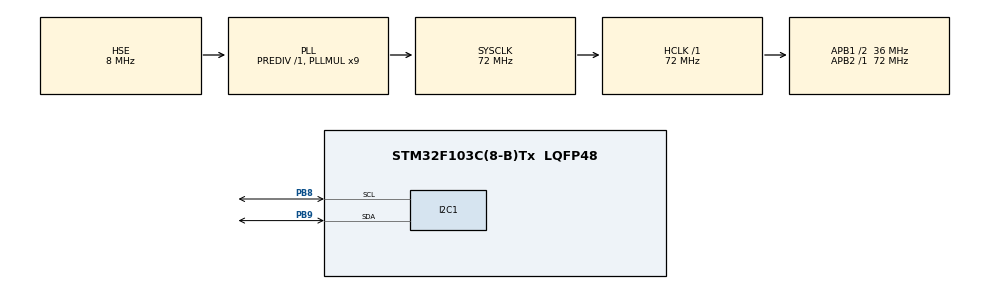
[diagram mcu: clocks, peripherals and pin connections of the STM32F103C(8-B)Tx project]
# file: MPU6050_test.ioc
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Mcu.Family=STM32F1
RCC.PLLSourceVirtual=RCC_PLLSOURCE_HSE
PD1-OSC_OUT.Mode=HSE-External-Oscillator
PD0-OSC_IN.Signal=RCC_OSC_IN
RCC.APB1CLKDivider=RCC_HCLK_DIV2
RCC.SYSCLKSource=RCC_SYSCLKSOURCE_PLLCLK
ProjectManager.StackSize=0x400
PD1-OSC_OUT.Signal=RCC_OSC_OUT
PA13.Signal=SYS_JTMS-SWDIO
ProjectManager.TargetToolchain=STM32CubeIDE
RCC.HCLKFreq_Value=72000000
PB9.Mode=I2C
RCC.APB2TimFreq_Value=72000000
RCC.USBFreq_Value=72000000
RCC.AHBFreq_Value=72000000
PD0-OSC_IN.Mode=HSE-External-Oscillator
board=custom
RCC.PLLMUL=RCC_PLL_MUL9
RCC.APB2Freq_Value=72000000
PA14.Mode=Serial_Wire
PA13.Mode=Serial_Wire
Mcu.Name=STM32F103C(8-B)Tx
RCC.SYSCLKFreq_VALUE=72000000
PB9.Signal=I2C1_SDA
Mcu.Package=LQFP48
PA14.Signal=SYS_JTCK-SWCLK
ProjectManager.HeapSize=0x200
NVIC.PriorityGroup=NVIC_PRIORITYGROUP_4
PB8.Mode=I2C
RCC.APB1TimFreq_Value=72000000
PB8.Signal=I2C1_SCL
RCC.APB1Freq_Value=36000000

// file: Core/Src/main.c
/* USER CODE BEGIN Header */
/**
  ******************************************************************************
  * @file           : main.c
  * @brief          : Main program body
  ******************************************************************************
  * @attention
  *
  * <h2><center>&copy; Copyright (c) 2021 STMicroelectronics.
  * All rights reserved.</center></h2>
  *
  * This software component is licensed by ST under BSD 3-Clause license,
  * the "License"; You may not use this file except in compliance with the
  * License. You may obtain a copy of the License at:
  *                        opensource.org/licenses/BSD-3-Clause
  *
  ******************************************************************************
  */
/* USER CODE END Header */
#include "main.h"

I2C_HandleTypeDef hi2c1;

/* USER CODE BEGIN PV */

static const uint8_t MPU_TempRegLSB = 0x41 << 1;
static const uint8_t MPU_TempRegMSB = 0x42 << 1;

/* USER CODE END PV */

void SystemClock_Config(void);
static void MX_GPIO_Init(void);
static void MX_I2C1_Init(void);

/* USER CODE BEGIN 0 */

#define MPU6050_ADDR 0x68 << 1
#define WHO_AM_I_REG 0X75
#define PWR_MGMT_1_REG 0x6B
#define SMPLRT_DIV 0x19
#define MPU_TempRegMSB 0x41

/* USER CODE END 0 */

int main(void)
{
  /* USER CODE BEGIN 1 */

	// En enumeration der beskriver en evt. fejl
	HAL_StatusTypeDef returnValue;
	uint8_t tempBuf[16];
	int16_t rawTempVal;
	float tempVal;

	void MPU6050_Init(void){
			uint8_t check, Data;

			// Check device ID who am I?
			// (Target device address, Internal memory address, Size of internal memory address, Pointer to data buffer, Amount of data to be sent, Timeout duration)
			HAL_I2C_Mem_Read(&hi2c1, MPU6050_ADDR, WHO_AM_I_REG, 1, &check, 1, 1000);

			if (check == 104){
				Data = 0;
				// Power management register 0x6B is set to all zeros to wake the device up
				HAL_I2C_Mem_Write(&hi2c1, MPU6050_ADDR, PWR_MGMT_1_REG, 1, &Data, 1 , 1000);

				// Set the data rate to 1 kHz by writing to SMPLRT_DIV register
				Data = 0x07;
				HAL_I2C_Mem_Write(&hi2c1, MPU6050_ADDR, SMPLRT_DIV, 1, &Data, 1 , 1000);
			}
		}

  /* USER CODE END 1 */

  /* MCU Configuration--------------------------------------------------------*/

  /* Reset of all peripherals, Initializes the Flash interface and the Systick. */
  HAL_Init();

  /* Configure the system clock */
  SystemClock_Config();

  /* Initialize all configured peripherals */
  MX_GPIO_Init();
  MX_I2C1_Init();
  /* USER CODE BEGIN 2 */

  MPU6050_Init();

  /* USER CODE END 2 */

  /* Infinite loop */
  /* USER CODE BEGIN WHILE */
  while (1)
  {
	  tempBuf[0] = MPU_TempRegMSB;

	  HAL_I2C_Mem_Read(&hi2c1, MPU6050_ADDR, MPU_TempRegMSB, 1, tempBuf, 2, HAL_MAX_DELAY);

		  // sammensætning af rå data
		  rawTempVal = ((int16_t)tempBuf[0] << 8 | tempBuf[1]);
		  tempVal = (rawTempVal)/340 + 36.53;
		  rawTempVal = ((int16_t)tempBuf[0] << 8 | tempBuf[1]);

    /* USER CODE END WHILE */

  }
}

void SystemClock_Config(void)
{
  RCC_OscInitTypeDef RCC_OscInitStruct = {0};
  RCC_ClkInitTypeDef RCC_ClkInitStruct = {0};

  /** Initializes the RCC Oscillators according to the specified parameters
  * in the RCC_OscInitTypeDef structure.
  */
  RCC_OscInitStruct.OscillatorType = RCC_OSCILLATORTYPE_HSE;
  RCC_OscInitStruct.HSEState = RCC_HSE_ON;
  RCC_OscInitStruct.HSEPredivValue = RCC_HSE_PREDIV_DIV1;
  RCC_OscInitStruct.HSIState = RCC_HSI_ON;
  RCC_OscInitStruct.PLL.PLLState = RCC_PLL_ON;
  RCC_OscInitStruct.PLL.PLLSource = RCC_PLLSOURCE_HSE;
  RCC_OscInitStruct.PLL.PLLMUL = RCC_PLL_MUL9;
  if (HAL_RCC_OscConfig(&RCC_OscInitStruct) != HAL_OK)
  {
    Error_Handler();
  }
  /** Initializes the CPU, AHB and APB buses clocks
  */
  RCC_ClkInitStruct.ClockType = RCC_CLOCKTYPE_HCLK|RCC_CLOCKTYPE_SYSCLK
                              |RCC_CLOCKTYPE_PCLK1|RCC_CLOCKTYPE_PCLK2;
  RCC_ClkInitStruct.SYSCLKSource = RCC_SYSCLKSOURCE_PLLCLK;
  RCC_ClkInitStruct.AHBCLKDivider = RCC_SYSCLK_DIV1;
  RCC_ClkInitStruct.APB1CLKDivider = RCC_HCLK_DIV2;
  RCC_ClkInitStruct.APB2CLKDivider = RCC_HCLK_DIV1;

  if (HAL_RCC_ClockConfig(&RCC_ClkInitStruct, FLASH_LATENCY_2) != HAL_OK)
  {
    Error_Handler();
  }
}

static void MX_I2C1_Init(void)
{

  hi2c1.Instance = I2C1;
  hi2c1.Init.ClockSpeed = 100000;
  hi2c1.Init.DutyCycle = I2C_DUTYCYCLE_2;
  hi2c1.Init.OwnAddress1 = 0;
  hi2c1.Init.AddressingMode = I2C_ADDRESSINGMODE_7BIT;
  hi2c1.Init.DualAddressMode = I2C_DUALADDRESS_DISABLE;
  hi2c1.Init.OwnAddress2 = 0;
  hi2c1.Init.GeneralCallMode = I2C_GENERALCALL_DISABLE;
  hi2c1.Init.NoStretchMode = I2C_NOSTRETCH_DISABLE;
  if (HAL_I2C_Init(&hi2c1) != HAL_OK)
  {
    Error_Handler();
  }

}

static void MX_GPIO_Init(void)
{

  /* GPIO Ports Clock Enable */
  __HAL_RCC_GPIOD_CLK_ENABLE();
  __HAL_RCC_GPIOA_CLK_ENABLE();
  __HAL_RCC_GPIOB_CLK_ENABLE();

}

void Error_Handler(void)
{
  __disable_irq();
  while (1)
  {
  }
}

/************************ (C) COPYRIGHT STMicroelectronics *****END OF FILE****/
